# max32650 register map
Vendor: Maxim-Integrated; Series: ARMCM4; File version: 1.0
CPU: CM4 r2p1, little endian, MPU, FPU, 3 interrupt priority bits
Registers are 32-bit, read-write, reset 0x0 unless marked. A register's access mark holds for its fields unless they carry their own. Offsets are from the block's base; [hi:lo] are bit positions; {n}, {i} and the like mark numbered series.

## FLC — Flash Memory Control.
Base 0x40029000; register names take the prefix FLSH_
0x00 ADDR — Flash Write Address.
  [31:0] ADDR — Address for next operation.
0x04 CLKDIV reset 0x64 — Flash Clock Divide. The clock (PLL0) is divided by this value to generate a 1 MHz clock for Flash controller.
  [7:0] CLKDIV — Flash Clock Divide. The clock is divided by this value to generate a 1MHz clock for flash controller.
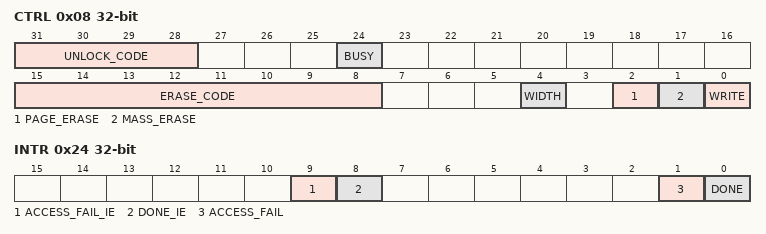
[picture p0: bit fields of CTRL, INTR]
0x08 CTRL — Flash Control Register.
  [31:28] UNLOCK_CODE — Flash Unlock. The correct unlock code must be written to these four bits before any Flash write or erase operation is allowed.
    2=unlocked (Flash Unlocked.); 3=locked (Flash Locked.)
  [24] BUSY ro — Flash Pending. When Flash operation is in progress (busy), Flash reads and writes will fail. When PEND is set, write to all Flash registers, with exception of the Flash interrupt register, are ignored.
    0=idle; 1=busy
  [15:8] ERASE_CODE — Erase Code. The ERASE_CODE must be set up property before erase operation can be initiated. These bits are automatically cleared after the operation is complete.
    0=dis (Flash erases disabled.); 85=pge (Enable Page Erase.); 170=me (Enable Mass Erase. The debug port must be enabled.)
  [4] WIDTH — This field sets the width of a write to the flash page. Select between 128-bit (default) and 32-bit.
    0=128_bit (Flash is written to in 128-bit increments.); 1=32_bit (Flash is written to in 32-bit increments.)
  [2] PAGE_ERASE — Page Erase. This bit is automatically cleared after the operation.
    0=complete (No operation/complete.); 1=start_pge (Start operation.)
  [1] MASS_ERASE — Mass Erase. This bit is automatically cleared after the operation.
    0=complete (No operation/complete.); 1=start_me (Start operation.)
  [0] WRITE — Write. This bit is automatically cleared after the operation.
    0=complete (No operation/complete.); 1=start_wr (Start operation.)
0x24 INTR — Flash Interrupt Register.
  [9] ACCESS_FAIL_IE
    0=dis (Disable.); 1=en (Enable.)
  [8] DONE_IE — Flash Done Interrupt Enable.
    0=dis (Disable.); 1=en (Enable.)
  [1] ACCESS_FAIL — Flash Access Fail. This bit is set when an attempt is made to write the flash while the flash is busy or the flash is locked. This bit can only be set to 1 by hardware.
    0=noerr (No Failure.); 1=error (Failure occurs.)
  [0] DONE — Flash Done Interrupt. This bit is set to 1 upon Flash write or erase completion.
    0=inactive (No interrupt is pending.); 1=pending (An interrupt is pending.)
{0x30+4i} DATA[{i}] (i=0..3) — Flash Write Data.
  [31:0] DATA — Data next operation.
0x40 ACTNL wo — Access Control Register. Writing the ACNTL register with the following values in the order shown, allows read and write access to the system and user Information block: pflc-acntl = 0x3a7f5ca3; pflc-acntl = 0xa1e34f20; pflc-acntl = 0x9608b2c1. When unlocked, a write of any word will disable access to system and user information block. Readback of this register is always zero.
  [31:0] ACNTL — Access control.

## HPB — HyperBus Memory Controller
Base 0x40039000
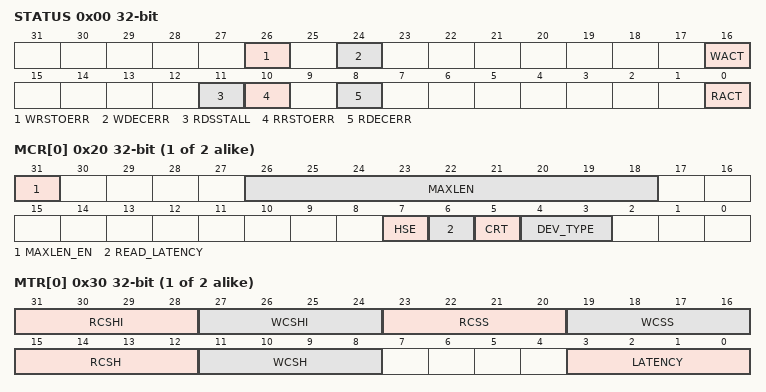
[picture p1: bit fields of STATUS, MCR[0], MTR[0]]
0x00 STATUS reset not defined — HPB Status Register.
  [26] WRSTOERR — Reset during write error.
    0=No error; 1=err (Error.)
  [24] WDECERR — Write address error.
    0=No error; 1=err (Error.)
  [16] WACT — Write transaction in progress.
    0=No write transaction in progress; 1=Write transaction in progress
  [11] RDSSTALL — Read data stall.
    0=normalop (Read operation normal.); 1=stalled (Read stalled.)
  [10] RRSTOERR — Reset during read error.
    0=No error; 1=err (Error.)
  [8] RDECERR — Read address error.
    0=No error; 1=err (Error.)
  [0] RACT — Read transaction in progress.
    0=No read transaction in progress; 1=Read transaction in progress
0x04 INTEN reset not defined — HPB Interrupt Enable.
  [1] ERRINTE — Error interrupt enable.
    0=dis (Disable error interrupt.); 1=en (Enable error interrupt.)
0x08 INTFL reset not defined — HPB Interrupt Status Flags.
  [1] ERRINT — Error interrupt status flags.
    0=No interrupt pending; 1=pending (Error interrupt pending.)
{0x10+4i} MBR[{i}] (i=0..1) reset not defined — HPB Memory Base Address.
  [31:24] ADDR — Memory Base Address.
{0x20+4i} MCR[{i}] (i=0..1) reset not defined — HPB Memory Configuration Register.
  [31] MAXLEN_EN — Maximum CS# length enable.
    0=dis (Configurable CS# low time disabled.); 1=en (Configurable CS# low time enabled.)
  [26:18] MAXLEN — Maximum read/write..
  [7] HSE — Xccela half sleep exit.
    0=dis (Half-Sleep exit disabled.); 1=en (Half-Sleep exit enabled.)
  [6] READ_LATENCY — Xccela fixed read latency enable.
    0=Variable read latency; 1=Fixed read latency
  [5] CRT — Configuration register target select.
    0=mem_space (Access memory space.); 1=config_reg_space (Access configuration register space.)
  [4:3] DEV_TYPE — Memory device type select.
    0=hyperFlash; 1=xccelaPSRAM; 2=hyperRAM
{0x30+4i} MTR[{i}] (i=0..1) reset not defined — HPB Memory Timing Register.
  [31:28] RCSHI — Read chip select high between operations.
  [27:24] WCSHI — Write chip select high between operations.
  [23:20] RCSS — Read chip select setup time to next CK rising edge.
  [19:16] WCSS — Write chip select setup time to next CK rising edge.
  [15:12] RCSH — Read chip select hold after CK falling edge.
  [11:8] WCSH — Write chip select hold after CK falling edge.
  [3:0] LATENCY — RAM Latency Clock Cycles.
    0=5CLK (5 clock cycles.); 1=6CLK (6 clock cycles.); 14=3CLK (3 clock cycles.); 15=4CLK (4 clock cycles.)
